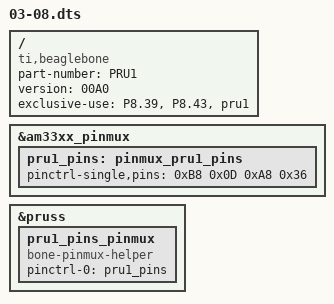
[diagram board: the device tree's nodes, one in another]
/dts-v1/;  
/plugin/;  

/{  
   compatible = "ti,beaglebone", "ti,beaglebone-green", "ti,beaglebone-black";  
   part-number = "PRU1";
   version = "00A0";
   exclusive-use =  
      "P8.39","P8.43","pru1";  
   
   fragment@0 {  
   	target = <&am33xx_pinmux>;  
    	__overlay__ {  
      		pru1_pins: pinmux_pru1_pins {  
      			pinctrl-single,pins = <0xB8 0x0D 0xA8 0x36>;  
      		};  
    	};  
   };  
     
   fragment@1 {
        target = <&pruss>;
        __overlay__ {
            pru1_pins_pinmux {
                compatible = "bone-pinmux-helper";
                status = "okay";
                pinctrl-names = "default";
                pinctrl-0 = <&pru1_pins>;
            };
        };
   };

};  
  
  
